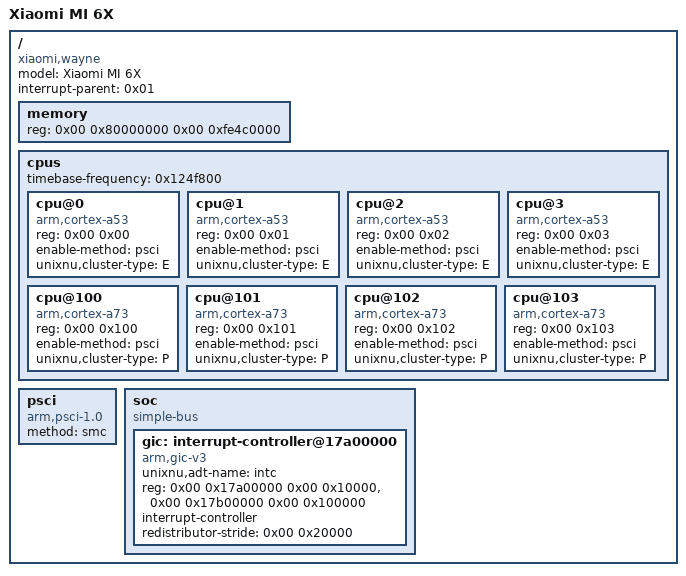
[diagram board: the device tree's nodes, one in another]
// SPDX-License-Identifier: BSD-3-Clause
// Xiaomi MI 6X (wayne), Qualcomm SDM660.
//
// This is the UniXNU hardware description, not the stock vendor device tree:
// the ADT generator translates every enabled node, so only annotated hardware
// belongs here. The stock dump is kept in the porting record for driver work.
//
// Hardware facts: msm-id 317, board-id 0x00040008, 4 GiB DDR at 0x80000000,
// GICv3 (GICD 0x17a00000, GICR 0x17b00000, stride 0x20000), XO 19.2 MHz,
// eMMC on sdhci@0xc0c4000, cont_splash at 0x9d400000.

/dts-v1/;

/ {
	model = "Xiaomi MI 6X";
	compatible = "xiaomi,wayne", "qcom,sdm660";
	#address-cells = <0x02>;
	#size-cells = <0x02>;
	interrupt-parent = <0x01>;

	memory {
		device_type = "memory";
		/* Bank 1 ends at 0x100000000 and bank 2 starts there. */
		reg = <0x00 0x80000000 0x00 0xfe4c0000>;
	};

	cpus {
		#address-cells = <0x02>;
		#size-cells = <0x00>;
		timebase-frequency = <0x124f800>;

		cpu@0 {
			device_type = "cpu";
			compatible = "arm,cortex-a53";
			reg = <0x00 0x00>;
			enable-method = "psci";
			unixnu,cluster-type = "E";
		};

		cpu@1 {
			device_type = "cpu";
			compatible = "arm,cortex-a53";
			reg = <0x00 0x01>;
			enable-method = "psci";
			unixnu,cluster-type = "E";
		};

		cpu@2 {
			device_type = "cpu";
			compatible = "arm,cortex-a53";
			reg = <0x00 0x02>;
			enable-method = "psci";
			unixnu,cluster-type = "E";
		};

		cpu@3 {
			device_type = "cpu";
			compatible = "arm,cortex-a53";
			reg = <0x00 0x03>;
			enable-method = "psci";
			unixnu,cluster-type = "E";
		};

		cpu@100 {
			device_type = "cpu";
			compatible = "arm,cortex-a73";
			reg = <0x00 0x100>;
			enable-method = "psci";
			unixnu,cluster-type = "P";
		};

		cpu@101 {
			device_type = "cpu";
			compatible = "arm,cortex-a73";
			reg = <0x00 0x101>;
			enable-method = "psci";
			unixnu,cluster-type = "P";
		};

		cpu@102 {
			device_type = "cpu";
			compatible = "arm,cortex-a73";
			reg = <0x00 0x102>;
			enable-method = "psci";
			unixnu,cluster-type = "P";
		};

		cpu@103 {
			device_type = "cpu";
			compatible = "arm,cortex-a73";
			reg = <0x00 0x103>;
			enable-method = "psci";
			unixnu,cluster-type = "P";
		};
	};

	psci {
		compatible = "arm,psci-1.0";
		method = "smc";
	};

	soc {
		compatible = "simple-bus";
		#address-cells = <0x02>;
		#size-cells = <0x02>;
		ranges;

		gic: interrupt-controller@17a00000 {
			compatible = "arm,gic-v3";
			unixnu,adt-name = "intc";
			reg = <0x00 0x17a00000 0x00 0x10000>,
			      <0x00 0x17b00000 0x00 0x100000>;
			#interrupt-cells = <0x04>;
			#address-cells = <0x00>;
			interrupt-controller;
			redistributor-stride = <0x00 0x20000>;
		};
	};
};
